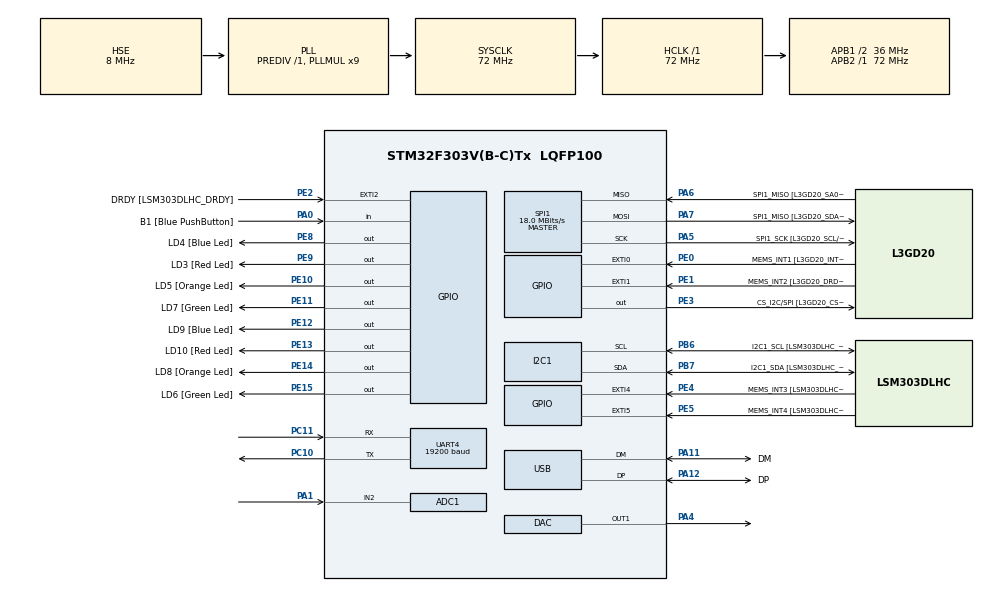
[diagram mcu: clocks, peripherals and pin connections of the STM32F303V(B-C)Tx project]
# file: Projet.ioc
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Mcu.Family=STM32F3
PA6.Mode=Full_Duplex_Master
RCC.CortexFreq_Value=72000000
SPI1.VirtualType=VM_MASTER
ADC1.ContinuousConvMode=ENABLE
PE11.GPIO_Label=LD7 [Green Led]
PC10.Signal=UART4_TX
PA14.GPIO_Label=SWCLK
RCC.SYSCLKSourceVirtual=RCC_SYSCLKSOURCE_PLLCLK
PA0.GPIO_Label=B1 [Blue PushButton]
Dma.DAC_CH1.1.MemInc=DMA_MINC_ENABLE
PA11.Mode=Device
PA6.GPIO_Label=SPI1_MISO [L3GD20_SA0/SDO]
PB6.GPIO_Label=I2C1_SCL [LSM303DLHC_SCL]
PC15-OSC32_OUT.GPIO_Label=OSC32_OUT
ProjectManager.StackSize=0x400
SPI1.Mode-Full_Duplex_Master=SPI_MODE_MASTER
NVIC.DMA1_Channel3_IRQn=true\:0\:0\:false\:false\:true\:false\:true
PA12.Signal=USB_DP
ADC1.Offset-0\#ChannelRegularConversion=0
SPI1.Direction=SPI_DIRECTION_2LINES
UART4.BaudRate=19200
RCC.HCLKFreq_Value=72000000
RCC.APB2TimFreq_Value=72000000
PB6.Signal=I2C1_SCL
Dma.ADC1.0.Direction=DMA_PERIPH_TO_MEMORY
PB6.Mode=I2C
SPI1.CalculateBaudRate=18.0 MBits/s
PE5.Signal=GPXTI5
PE1.Signal=GPXTI1
Dma.ADC1.0.MemDataAlignment=DMA_MDATAALIGN_HALFWORD
RCC.AHBFreq_Value=72000000
ADC1.Channel-0\#ChannelRegularConversion=ADC_CHANNEL_2
RCC.HSE_VALUE=8000000
PF0-OSC_IN.GPIO_Label=OSC_IN
RCC.PLLMUL=RCC_PLL_MUL9
PE13.Signal=GPIO_Output
DAC.DAC_Trigger=DAC_TRIGGER_T2_TRGO
PE9.Signal=GPIO_Output
PA14.Mode=Serial_Wire
Dma.ADC1.0.PeriphInc=DMA_PINC_DISABLE
PE4.GPIO_Label=MEMS_INT3 [LSM303DLHC_INT1]
PE2.Signal=GPXTI2
PB7.Signal=I2C1_SDA
PE10.Signal=GPIO_Output
PE4.Signal=GPXTI4
ADC1.SamplingTime-0\#ChannelRegularConversion=ADC_SAMPLETIME_1CYCLE_5
SPI1.CalculateBaudRate-Full_Duplex_Master=24.0 MBits/s
PA0.Signal=GPIO_Input
Dma.DAC_CH1.1.PeriphDataAlignment=DMA_PDATAALIGN_BYTE
PB7.GPIO_Label=I2C1_SDA [LSM303DLHC_SDA]
Mcu.Package=LQFP100
TIM2.Prescaler=42-1
PA6.Signal=SPI1_MISO
PE12.GPIO_Label=LD9 [Blue Led]
PC11.Mode=Asynchronous
PE0.GPIO_Label=MEMS_INT1 [L3GD20_INT1]
TIM2.TIM_MasterOutputTrigger=TIM_TRGO_UPDATE
Dma.Request1=DAC_CH1
RCC.APB1TimFreq_Value=72000000
PC14-OSC32_IN.GPIO_Label=OSC32_IN
PE10.GPIO_Label=LD5 [Orange Led]
Dma.Request0=ADC1
SPI1.BaudRatePrescaler=SPI_BAUDRATEPRESCALER_4
PE2.GPIO_Label=DRDY [LSM303DLHC_DRDY]
PF1-OSC_OUT.Signal=RCC_OSC_OUT
Dma.DAC_CH1.1.Mode=DMA_CIRCULAR
PA5.Mode=Full_Duplex_Master
PB3.GPIO_Label=SWO
SH.COMP_DAC1_group.0=DAC_OUT1,DAC_OUT1
Dma.ADC1.0.Instance=DMA1_Channel1
ADC1.Rank-0\#ChannelRegularConversion=1
PA7.Mode=Full_Duplex_Master
ADC1.OffsetNumber-0\#ChannelRegularConversion=ADC_OFFSET_NONE
PC11.Signal=UART4_RX
PC10.Mode=Asynchronous
PE4.GPIO_ModeDefaultEXTI=GPIO_MODE_EVT_RISING
PA11.GPIO_Label=DM
PE14.GPIO_Label=LD8 [Orange Led]
PE1.GPIO_ModeDefaultEXTI=GPIO_MODE_EVT_RISING
RCC.APB1CLKDivider=RCC_HCLK_DIV2
PC14-OSC32_IN.Signal=RCC_OSC32_IN
Dma.DAC_CH1.1.Instance=DMA1_Channel3
PA12.GPIO_Label=DP
PA13.Signal=SYS_JTMS-SWDIO
Dma.ADC1.0.PeriphDataAlignment=DMA_PDATAALIGN_HALFWORD
PE15.GPIO_Label=LD6 [Green Led]
ProjectManager.TargetToolchain=STM32CubeIDE
PE5.GPIO_ModeDefaultEXTI=GPIO_MODE_EVT_RISING
ADC1.SamplingTimeOPAMP-0\#ChannelRegularConversion=ADC_SAMPLETIME_61CYCLES_5
Dma.ADC1.0.Mode=DMA_CIRCULAR
Dma.DAC_CH1.1.PeriphInc=DMA_PINC_DISABLE
PE8.GPIO_Label=LD4 [Blue Led]
PE0.GPIO_ModeDefaultEXTI=GPIO_MODE_EVT_RISING
Dma.ADC1.0.Priority=DMA_PRIORITY_LOW
RCC.USBFreq_Value=48000000
PE11.Signal=GPIO_Output
RCC.LSE_VALUE=32768
PC15-OSC32_OUT.Signal=RCC_OSC32_OUT
PE9.GPIO_Label=LD3 [Red Led]
PA1.Signal=ADC1_IN2
PF0-OSC_IN.Mode=HSE-External-Clock-Source
PA5.Signal=SPI1_SCK
board=STM32F3DISCOVERY
PE1.GPIO_Label=MEMS_INT2 [L3GD20_DRDY/INT2]
RCC.APB2Freq_Value=72000000
PE14.Signal=GPIO_Output
PA1.Mode=IN2-Single-Ended
PE15.Signal=GPIO_Output
Dma.DAC_CH1.1.Direction=DMA_MEMORY_TO_PERIPH
RCC.PRESCALERUSB=RCC_USBCLKSOURCE_PLL_DIV1_5
VP_TIM2_VS_ClockSourceINT.Mode=Internal
PE8.Signal=GPIO_Output
SPI1.Mode=SPI_MODE_MASTER
Dma.DAC_CH1.1.MemDataAlignment=DMA_MDATAALIGN_BYTE
PF1-OSC_OUT.GPIO_Label=OSC_OUT
I2C1.Timing-I2C=0x2000090E
ADC1.DMAContinuousRequests=ENABLE
TIM2.Period=10-1
PA13.Mode=Serial_Wire
Mcu.Name=STM32F303V(B-C)Tx
PE0.Signal=GPXTI0
PE12.Signal=GPIO_Output
PA13.GPIO_Label=SWDIO
PB3.Signal=SYS_JTDO-TRACESWO
PA4.Signal=COMP_DAC1_group
RCC.SYSCLKFreq_VALUE=72000000
PA7.GPIO_Label=SPI1_MISO [L3GD20_SDA/SDI/SDO]
ADC1.master=1
Dma.DAC_CH1.1.Priority=DMA_PRIORITY_HIGH
PE13.GPIO_Label=LD10 [Red Led]
PA12.Mode=Device
PA5.GPIO_Label=SPI1_SCK [L3GD20_SCL/SPC]
PE5.GPIO_Label=MEMS_INT4 [LSM303DLHC_INT2]
PB7.Mode=I2C
PA11.Signal=USB_DM
PA14.Signal=SYS_JTCK-SWCLK
Dma.ADC1.0.MemInc=DMA_MINC_ENABLE
ProjectManager.HeapSize=0x200
RCC.HSI_VALUE=8000000
NVIC.PriorityGroup=NVIC_PRIORITYGROUP_0
ADC1.NbrOfConversionFlag=1
PE3.Signal=GPIO_Output
PE3.GPIO_Label=CS_I2C/SPI [L3GD20_CS_I2C/SPI]
PE2.GPIO_ModeDefaultEXTI=GPIO_MODE_EVT_RISING
NVIC.DMA1_Channel1_IRQn=true\:0\:0\:false\:false\:true\:false\:true
PF0-OSC_IN.Signal=RCC_OSC_IN
RCC.ADC12PRES=RCC_ADC12PLLCLK_DIV16
RCC.APB1Freq_Value=36000000
ADC1.ClockPrescaler=ADC_CLOCK_ASYNC_DIV1
SPI1.BaudRatePrescaler-Full_Duplex_Master=SPI_BAUDRATEPRESCALER_2
PA7.Signal=SPI1_MOSI

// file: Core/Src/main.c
/* USER CODE BEGIN Header */
/**
  ******************************************************************************
  * @file           : main.c
  * @brief          : Main program body
  ******************************************************************************
  * @attention
  *
  * <h2><center>&copy; Copyright (c) 2021 STMicroelectronics.
  * All rights reserved.</center></h2>
  *
  * This software component is licensed by ST under BSD 3-Clause license,
  * the "License"; You may not use this file except in compliance with the
  * License. You may obtain a copy of the License at:
  *                        opensource.org/licenses/BSD-3-Clause
  *
  ******************************************************************************
  */
/* USER CODE END Header */
#include "main.h"

ADC_HandleTypeDef hadc1;
DMA_HandleTypeDef hdma_adc1;

DAC_HandleTypeDef hdac;
DMA_HandleTypeDef hdma_dac_ch1;

I2C_HandleTypeDef hi2c1;

SPI_HandleTypeDef hspi1;

TIM_HandleTypeDef htim2;

UART_HandleTypeDef huart4;

PCD_HandleTypeDef hpcd_USB_FS;

void SystemClock_Config(void);
static void MX_GPIO_Init(void);
static void MX_DMA_Init(void);
static void MX_ADC1_Init(void);
static void MX_I2C1_Init(void);
static void MX_SPI1_Init(void);
static void MX_USB_PCD_Init(void);
static void MX_DAC_Init(void);
static void MX_TIM2_Init(void);
static void MX_UART4_Init(void);

/* USER CODE BEGIN 0 */
const uint8_t myDAC_Signal[65] = {127, 139,151,163,175,186,197,207,216,225,232,239,244,248,251,253,254,253,251,248,244,239,232,225,216,207,197,186,175,163,151,139,127,115,103,91,79,68,57,47,38,29,22,15,10,6,3,1,0,1,3,6,10,15,22,29,38,47,57,68,79,91,103,115,127};
/* USER CODE END 0 */

int main(void)
{

  /* MCU Configuration--------------------------------------------------------*/

  /* Reset of all peripherals, Initializes the Flash interface and the Systick. */
  HAL_Init();

  /* Configure the system clock */
  SystemClock_Config();

  /* Initialize all configured peripherals */
  MX_GPIO_Init();
  MX_DMA_Init();
  MX_ADC1_Init();
  MX_I2C1_Init();
  MX_SPI1_Init();
  MX_USB_PCD_Init();
  MX_DAC_Init();
  MX_TIM2_Init();
  MX_UART4_Init();
  /* USER CODE BEGIN 2 */
	HAL_TIM_Base_Start(&htim2);
//	HAL_DACEx_NoiseWaveGenerate(&hdac, DAC_CHANNEL_1,DAC_TRIANGLEAMPLITUDE_2047);
//	HAL_DAC_Start(&hdac, DAC_CHANNEL_1);
//	HAL_DAC_SetValue(&hdac, DAC1_CHANNEL_1, DAC_ALIGN_12B_R, 1000);
	HAL_DAC_Start_DMA(&hdac, DAC1_CHANNEL_1, (uint32_t *)myDAC_Signal, 65, DAC_ALIGN_8B_R);
  /* USER CODE END 2 */

  /* Infinite loop */
  while (1)
  {

  }
}

void SystemClock_Config(void)
{
  RCC_OscInitTypeDef RCC_OscInitStruct = {0};
  RCC_ClkInitTypeDef RCC_ClkInitStruct = {0};
  RCC_PeriphCLKInitTypeDef PeriphClkInit = {0};

  /** Initializes the RCC Oscillators according to the specified parameters
  * in the RCC_OscInitTypeDef structure.
  */
  RCC_OscInitStruct.OscillatorType = RCC_OSCILLATORTYPE_HSI|RCC_OSCILLATORTYPE_HSE;
  RCC_OscInitStruct.HSEState = RCC_HSE_BYPASS;
  RCC_OscInitStruct.HSEPredivValue = RCC_HSE_PREDIV_DIV1;
  RCC_OscInitStruct.HSIState = RCC_HSI_ON;
  RCC_OscInitStruct.HSICalibrationValue = RCC_HSICALIBRATION_DEFAULT;
  RCC_OscInitStruct.PLL.PLLState = RCC_PLL_ON;
  RCC_OscInitStruct.PLL.PLLSource = RCC_PLLSOURCE_HSE;
  RCC_OscInitStruct.PLL.PLLMUL = RCC_PLL_MUL9;
  if (HAL_RCC_OscConfig(&RCC_OscInitStruct) != HAL_OK)
  {
    Error_Handler();
  }
  /** Initializes the CPU, AHB and APB buses clocks
  */
  RCC_ClkInitStruct.ClockType = RCC_CLOCKTYPE_HCLK|RCC_CLOCKTYPE_SYSCLK
                              |RCC_CLOCKTYPE_PCLK1|RCC_CLOCKTYPE_PCLK2;
  RCC_ClkInitStruct.SYSCLKSource = RCC_SYSCLKSOURCE_PLLCLK;
  RCC_ClkInitStruct.AHBCLKDivider = RCC_SYSCLK_DIV1;
  RCC_ClkInitStruct.APB1CLKDivider = RCC_HCLK_DIV2;
  RCC_ClkInitStruct.APB2CLKDivider = RCC_HCLK_DIV1;

  if (HAL_RCC_ClockConfig(&RCC_ClkInitStruct, FLASH_LATENCY_2) != HAL_OK)
  {
    Error_Handler();
  }
  PeriphClkInit.PeriphClockSelection = RCC_PERIPHCLK_USB|RCC_PERIPHCLK_UART4
                              |RCC_PERIPHCLK_I2C1|RCC_PERIPHCLK_ADC12;
  PeriphClkInit.Uart4ClockSelection = RCC_UART4CLKSOURCE_PCLK1;
  PeriphClkInit.Adc12ClockSelection = RCC_ADC12PLLCLK_DIV16;
  PeriphClkInit.I2c1ClockSelection = RCC_I2C1CLKSOURCE_HSI;
  PeriphClkInit.USBClockSelection = RCC_USBCLKSOURCE_PLL_DIV1_5;
  if (HAL_RCCEx_PeriphCLKConfig(&PeriphClkInit) != HAL_OK)
  {
    Error_Handler();
  }
}

static void MX_ADC1_Init(void)
{

  ADC_MultiModeTypeDef multimode = {0};
  ADC_ChannelConfTypeDef sConfig = {0};

  /** Common config
  */
  hadc1.Instance = ADC1;
  hadc1.Init.ClockPrescaler = ADC_CLOCK_ASYNC_DIV1;
  hadc1.Init.Resolution = ADC_RESOLUTION_12B;
  hadc1.Init.ScanConvMode = ADC_SCAN_DISABLE;
  hadc1.Init.ContinuousConvMode = ENABLE;
  hadc1.Init.DiscontinuousConvMode = DISABLE;
  hadc1.Init.ExternalTrigConvEdge = ADC_EXTERNALTRIGCONVEDGE_NONE;
  hadc1.Init.ExternalTrigConv = ADC_SOFTWARE_START;
  hadc1.Init.DataAlign = ADC_DATAALIGN_RIGHT;
  hadc1.Init.NbrOfConversion = 1;
  hadc1.Init.DMAContinuousRequests = ENABLE;
  hadc1.Init.EOCSelection = ADC_EOC_SINGLE_CONV;
  hadc1.Init.LowPowerAutoWait = DISABLE;
  hadc1.Init.Overrun = ADC_OVR_DATA_OVERWRITTEN;
  if (HAL_ADC_Init(&hadc1) != HAL_OK)
  {
    Error_Handler();
  }
  /** Configure the ADC multi-mode
  */
  multimode.Mode = ADC_MODE_INDEPENDENT;
  if (HAL_ADCEx_MultiModeConfigChannel(&hadc1, &multimode) != HAL_OK)
  {
    Error_Handler();
  }
  /** Configure Regular Channel
  */
  sConfig.Channel = ADC_CHANNEL_2;
  sConfig.Rank = ADC_REGULAR_RANK_1;
  sConfig.SingleDiff = ADC_SINGLE_ENDED;
  sConfig.SamplingTime = ADC_SAMPLETIME_1CYCLE_5;
  sConfig.OffsetNumber = ADC_OFFSET_NONE;
  sConfig.Offset = 0;
  if (HAL_ADC_ConfigChannel(&hadc1, &sConfig) != HAL_OK)
  {
    Error_Handler();
  }

}

static void MX_DAC_Init(void)
{

  DAC_ChannelConfTypeDef sConfig = {0};

  /** DAC Initialization
  */
  hdac.Instance = DAC;
  if (HAL_DAC_Init(&hdac) != HAL_OK)
  {
    Error_Handler();
  }
  /** DAC channel OUT1 config
  */
  sConfig.DAC_Trigger = DAC_TRIGGER_T2_TRGO;
  sConfig.DAC_OutputBuffer = DAC_OUTPUTBUFFER_ENABLE;
  if (HAL_DAC_ConfigChannel(&hdac, &sConfig, DAC_CHANNEL_1) != HAL_OK)
  {
    Error_Handler();
  }

}

static void MX_I2C1_Init(void)
{

  hi2c1.Instance = I2C1;
  hi2c1.Init.Timing = 0x2000090E;
  hi2c1.Init.OwnAddress1 = 0;
  hi2c1.Init.AddressingMode = I2C_ADDRESSINGMODE_7BIT;
  hi2c1.Init.DualAddressMode = I2C_DUALADDRESS_DISABLE;
  hi2c1.Init.OwnAddress2 = 0;
  hi2c1.Init.OwnAddress2Masks = I2C_OA2_NOMASK;
  hi2c1.Init.GeneralCallMode = I2C_GENERALCALL_DISABLE;
  hi2c1.Init.NoStretchMode = I2C_NOSTRETCH_DISABLE;
  if (HAL_I2C_Init(&hi2c1) != HAL_OK)
  {
    Error_Handler();
  }
  /** Configure Analogue filter
  */
  if (HAL_I2CEx_ConfigAnalogFilter(&hi2c1, I2C_ANALOGFILTER_ENABLE) != HAL_OK)
  {
    Error_Handler();
  }
  /** Configure Digital filter
  */
  if (HAL_I2CEx_ConfigDigitalFilter(&hi2c1, 0) != HAL_OK)
  {
    Error_Handler();
  }

}

static void MX_SPI1_Init(void)
{

  /* SPI1 parameter configuration*/
  hspi1.Instance = SPI1;
  hspi1.Init.Mode = SPI_MODE_MASTER;
  hspi1.Init.Direction = SPI_DIRECTION_2LINES;
  hspi1.Init.DataSize = SPI_DATASIZE_4BIT;
  hspi1.Init.CLKPolarity = SPI_POLARITY_LOW;
  hspi1.Init.CLKPhase = SPI_PHASE_1EDGE;
  hspi1.Init.NSS = SPI_NSS_SOFT;
  hspi1.Init.BaudRatePrescaler = SPI_BAUDRATEPRESCALER_4;
  hspi1.Init.FirstBit = SPI_FIRSTBIT_MSB;
  hspi1.Init.TIMode = SPI_TIMODE_DISABLE;
  hspi1.Init.CRCCalculation = SPI_CRCCALCULATION_DISABLE;
  hspi1.Init.CRCPolynomial = 7;
  hspi1.Init.CRCLength = SPI_CRC_LENGTH_DATASIZE;
  hspi1.Init.NSSPMode = SPI_NSS_PULSE_ENABLE;
  if (HAL_SPI_Init(&hspi1) != HAL_OK)
  {
    Error_Handler();
  }

}

static void MX_TIM2_Init(void)
{

  TIM_ClockConfigTypeDef sClockSourceConfig = {0};
  TIM_MasterConfigTypeDef sMasterConfig = {0};

  htim2.Instance = TIM2;
  htim2.Init.Prescaler = 42-1;
  htim2.Init.CounterMode = TIM_COUNTERMODE_UP;
  htim2.Init.Period = 10-1;
  htim2.Init.ClockDivision = TIM_CLOCKDIVISION_DIV1;
  htim2.Init.AutoReloadPreload = TIM_AUTORELOAD_PRELOAD_DISABLE;
  if (HAL_TIM_Base_Init(&htim2) != HAL_OK)
  {
    Error_Handler();
  }
  sClockSourceConfig.ClockSource = TIM_CLOCKSOURCE_INTERNAL;
  if (HAL_TIM_ConfigClockSource(&htim2, &sClockSourceConfig) != HAL_OK)
  {
    Error_Handler();
  }
  sMasterConfig.MasterOutputTrigger = TIM_TRGO_UPDATE;
  sMasterConfig.MasterSlaveMode = TIM_MASTERSLAVEMODE_DISABLE;
  if (HAL_TIMEx_MasterConfigSynchronization(&htim2, &sMasterConfig) != HAL_OK)
  {
    Error_Handler();
  }

}

static void MX_UART4_Init(void)
{

  huart4.Instance = UART4;
  huart4.Init.BaudRate = 19200;
  huart4.Init.WordLength = UART_WORDLENGTH_8B;
  huart4.Init.StopBits = UART_STOPBITS_1;
  huart4.Init.Parity = UART_PARITY_NONE;
  huart4.Init.Mode = UART_MODE_TX_RX;
  huart4.Init.HwFlowCtl = UART_HWCONTROL_NONE;
  huart4.Init.OverSampling = UART_OVERSAMPLING_16;
  huart4.Init.OneBitSampling = UART_ONE_BIT_SAMPLE_DISABLE;
  huart4.AdvancedInit.AdvFeatureInit = UART_ADVFEATURE_NO_INIT;
  if (HAL_UART_Init(&huart4) != HAL_OK)
  {
    Error_Handler();
  }

}

static void MX_USB_PCD_Init(void)
{

  hpcd_USB_FS.Instance = USB;
  hpcd_USB_FS.Init.dev_endpoints = 8;
  hpcd_USB_FS.Init.speed = PCD_SPEED_FULL;
  hpcd_USB_FS.Init.phy_itface = PCD_PHY_EMBEDDED;
  hpcd_USB_FS.Init.low_power_enable = DISABLE;
  hpcd_USB_FS.Init.battery_charging_enable = DISABLE;
  if (HAL_PCD_Init(&hpcd_USB_FS) != HAL_OK)
  {
    Error_Handler();
  }

}

static void MX_DMA_Init(void)
{

  /* DMA controller clock enable */
  __HAL_RCC_DMA1_CLK_ENABLE();

  /* DMA interrupt init */
  /* DMA1_Channel1_IRQn interrupt configuration */
  HAL_NVIC_SetPriority(DMA1_Channel1_IRQn, 0, 0);
  HAL_NVIC_EnableIRQ(DMA1_Channel1_IRQn);
  /* DMA1_Channel3_IRQn interrupt configuration */
  HAL_NVIC_SetPriority(DMA1_Channel3_IRQn, 0, 0);
  HAL_NVIC_EnableIRQ(DMA1_Channel3_IRQn);

}

static void MX_GPIO_Init(void)
{
  GPIO_InitTypeDef GPIO_InitStruct = {0};

  /* GPIO Ports Clock Enable */
  __HAL_RCC_GPIOE_CLK_ENABLE();
  __HAL_RCC_GPIOC_CLK_ENABLE();
  __HAL_RCC_GPIOF_CLK_ENABLE();
  __HAL_RCC_GPIOA_CLK_ENABLE();
  __HAL_RCC_GPIOB_CLK_ENABLE();

  /*Configure GPIO pin Output Level */
  HAL_GPIO_WritePin(GPIOE, CS_I2C_SPI_Pin|LD4_Pin|LD3_Pin|LD5_Pin
                          |LD7_Pin|LD9_Pin|LD10_Pin|LD8_Pin
                          |LD6_Pin, GPIO_PIN_RESET);

  /*Configure GPIO pins : DRDY_Pin MEMS_INT3_Pin MEMS_INT4_Pin MEMS_INT1_Pin
                           MEMS_INT2_Pin */
  GPIO_InitStruct.Pin = DRDY_Pin|MEMS_INT3_Pin|MEMS_INT4_Pin|MEMS_INT1_Pin
                          |MEMS_INT2_Pin;
  GPIO_InitStruct.Mode = GPIO_MODE_EVT_RISING;
  GPIO_InitStruct.Pull = GPIO_NOPULL;
  HAL_GPIO_Init(GPIOE, &GPIO_InitStruct);

  /*Configure GPIO pins : CS_I2C_SPI_Pin LD4_Pin LD3_Pin LD5_Pin
                           LD7_Pin LD9_Pin LD10_Pin LD8_Pin
                           LD6_Pin */
  GPIO_InitStruct.Pin = CS_I2C_SPI_Pin|LD4_Pin|LD3_Pin|LD5_Pin
                          |LD7_Pin|LD9_Pin|LD10_Pin|LD8_Pin
                          |LD6_Pin;
  GPIO_InitStruct.Mode = GPIO_MODE_OUTPUT_PP;
  GPIO_InitStruct.Pull = GPIO_NOPULL;
  GPIO_InitStruct.Speed = GPIO_SPEED_FREQ_LOW;
  HAL_GPIO_Init(GPIOE, &GPIO_InitStruct);

  /*Configure GPIO pin : B1_Pin */
  GPIO_InitStruct.Pin = B1_Pin;
  GPIO_InitStruct.Mode = GPIO_MODE_INPUT;
  GPIO_InitStruct.Pull = GPIO_NOPULL;
  HAL_GPIO_Init(B1_GPIO_Port, &GPIO_InitStruct);

}

void Error_Handler(void)
{
  __disable_irq();
  while (1)
  {
  }
}

/************************ (C) COPYRIGHT STMicroelectronics *****END OF FILE****/
